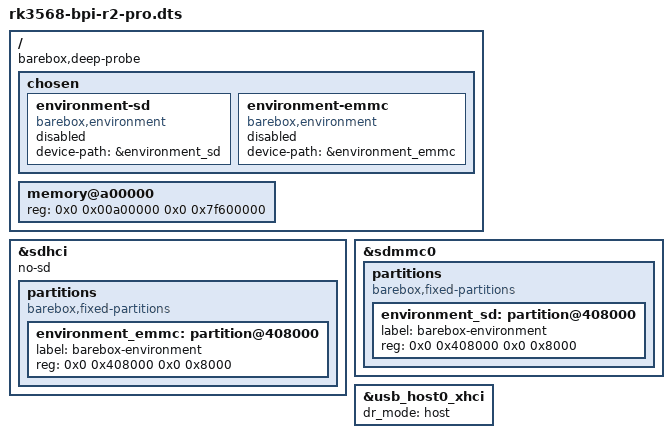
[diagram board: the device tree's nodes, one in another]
// SPDX-License-Identifier: (GPL-2.0+ OR MIT)
/*
 * Author: Frank Wunderlich <frank-w@public-files.de>
 *
 */

/dts-v1/;
#include "arm64/rockchip/rk3568-bpi-r2-pro.dts"
/ {
	barebox,deep-probe;

	chosen {
		environment-sd {
			compatible = "barebox,environment";
			device-path = &environment_sd;
			status = "disabled";
		};

		environment-emmc {
			compatible = "barebox,environment";
			device-path = &environment_emmc;
			status = "disabled";
		};
	};

	memory@a00000 {
		device_type = "memory";
		reg = <0x0 0x00a00000 0x0 0x7f600000>;
	};
};

&sdhci {
	no-sd;

	partitions {
		compatible = "barebox,fixed-partitions";
		#address-cells = <2>;
		#size-cells = <2>;

		environment_emmc: partition@408000 {
			label = "barebox-environment";
			reg = <0x0 0x408000 0x0 0x8000>;
		};
	};
};

&sdmmc0 {
	partitions {
		compatible = "barebox,fixed-partitions";
		#address-cells = <2>;
		#size-cells = <2>;

		environment_sd: partition@408000 {
			label = "barebox-environment";
			reg = <0x0 0x408000 0x0 0x8000>;
		};
	};
};

&usb_host0_xhci {
	dr_mode = "host";
};
